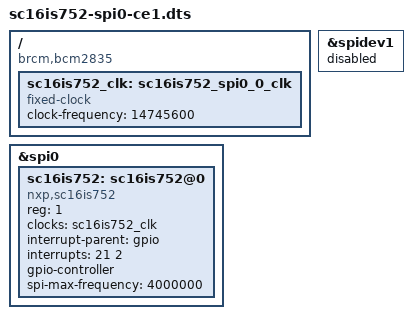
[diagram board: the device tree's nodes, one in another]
// Definitions for SC16IS752 UART on spi0.1
// src: https://github.com/raspberrypi/linux/blob/rpi-5.4.y/arch/arm/boot/dts/overlays/sc16is752-spi0-overlay.dts
// This code is released under GPL 2.0
/dts-v1/;
/plugin/;

/ {
	compatible = "brcm,bcm2835";

	fragment@0 {
		target = <&spi0>;
		__overlay__ {
			#address-cells = <1>;
			#size-cells = <0>;
			status = "okay";

			sc16is752: sc16is752@0 {
				compatible = "nxp,sc16is752";
				reg = <1>; /* CE1 */
				clocks = <&sc16is752_clk>;
				interrupt-parent = <&gpio>;
				interrupts = <21 2>; /* IRQ_TYPE_EDGE_FALLING */
				gpio-controller;
				#gpio-cells = <2>;
				spi-max-frequency = <4000000>;
			};
		};
	};

	fragment@1 {
		target = <&spidev1>;
		__overlay__ {
			status = "disabled";
		};
	};

	fragment@2 {
		target-path = "/";
		__overlay__ {
			sc16is752_clk: sc16is752_spi0_0_clk {
				compatible = "fixed-clock";
				#clock-cells = <0>;
				clock-frequency = <14745600>;
			};
		};
	};
};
